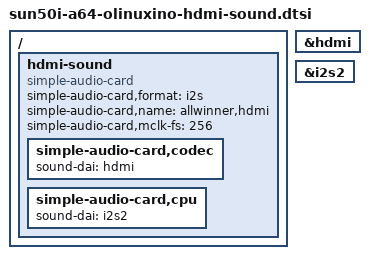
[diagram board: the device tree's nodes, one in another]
// SPDX-License-Identifier: (GPL-2.0+ OR MIT)
// Copyright (C) 2023 Pavel Sorejs

/ {
	hdmi-sound {
		compatible = "simple-audio-card";
		simple-audio-card,format = "i2s";
		simple-audio-card,name = "allwinner,hdmi";
		simple-audio-card,mclk-fs = <256>;
		status = "okay";

		simple-audio-card,codec {
			sound-dai = <&hdmi>;
		};

		simple-audio-card,cpu {
			sound-dai = <&i2s2>;
		};
	};  
};

&hdmi {
	#sound-dai-cells = <0>;
};

&i2s2 {
	status = "okay";
};
